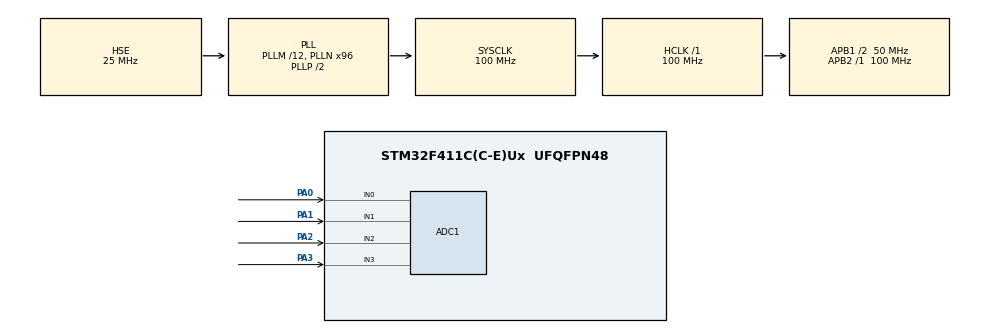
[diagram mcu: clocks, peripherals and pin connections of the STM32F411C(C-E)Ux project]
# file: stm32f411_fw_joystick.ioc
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Mcu.Family=STM32F4
RCC.PLLSourceVirtual=RCC_PLLSOURCE_HSE
PC15-OSC32_OUT.Mode=LSE-External-Oscillator
Dma.ADC1.0.Instance=DMA2_Stream0
RCC.CortexFreq_Value=100000000
ADC1.ContinuousConvMode=ENABLE
SH.ADCx_IN2.0=ADC1_IN2,IN2
ADC1.SamplingTime-6\#ChannelRegularConversion=ADC_SAMPLETIME_84CYCLES
ADC1.Rank-8\#ChannelRegularConversion=4
PH1\ -\ OSC_OUT.Mode=HSE-External-Oscillator
RCC.APB1CLKDivider=RCC_HCLK_DIV2
PC14-OSC32_IN.Signal=RCC_OSC32_IN
ADC1.SamplingTime-2\#ChannelRegularConversion=ADC_SAMPLETIME_84CYCLES
ADC1.Channel-8\#ChannelRegularConversion=ADC_CHANNEL_3
RCC.SYSCLKSource=RCC_SYSCLKSOURCE_PLLCLK
ProjectManager.StackSize=0x400
PA0-WKUP.Signal=ADCx_IN0
ADC1.Channel-7\#ChannelRegularConversion=ADC_CHANNEL_2
PA13.Signal=SYS_JTMS-SWDIO
Dma.ADC1.0.PeriphDataAlignment=DMA_PDATAALIGN_WORD
PH0\ -\ OSC_IN.Mode=HSE-External-Oscillator
PH0\ -\ OSC_IN.Signal=RCC_OSC_IN
ProjectManager.TargetToolchain=STM32CubeIDE
Dma.ADC1.0.Mode=DMA_CIRCULAR
RCC.HCLKFreq_Value=100000000
SH.ADCx_IN3.0=ADC1_IN3,IN3
Dma.ADC1.0.Priority=DMA_PRIORITY_MEDIUM
RCC.APB2TimFreq_Value=100000000
Dma.ADC1.0.Direction=DMA_PERIPH_TO_MEMORY
ADC1.Channel-2\#ChannelRegularConversion=ADC_CHANNEL_0
NVIC.DMA2_Stream0_IRQn=true\:0\:0\:false\:false\:true\:false\:true
PC15-OSC32_OUT.Signal=RCC_OSC32_OUT
Dma.ADC1.0.MemDataAlignment=DMA_MDATAALIGN_WORD
PA1.Signal=ADCx_IN1
RCC.AHBFreq_Value=100000000
RCC.HSE_VALUE=25000000
PH1\ -\ OSC_OUT.Signal=RCC_OSC_OUT
ADC1.ScanConvMode=ENABLE
board=custom
RCC.VCOOutputFreq_Value=200000000
ADC1.Channel-6\#ChannelRegularConversion=ADC_CHANNEL_1
RCC.APB2Freq_Value=100000000
ADC1.Rank-2\#ChannelRegularConversion=1
PC14-OSC32_IN.Mode=LSE-External-Oscillator
PA14.Mode=Serial_Wire
Dma.ADC1.0.PeriphInc=DMA_PINC_DISABLE
SH.ADCx_IN0.0=ADC1_IN0,IN0
ADC1.DMAContinuousRequests=ENABLE
ADC1.NbrOfConversion=4
PA13.Mode=Serial_Wire
Mcu.Name=STM32F411C(C-E)Ux
PA2.Signal=ADCx_IN2
RCC.48MHZClocksFreq_Value=50000000
RCC.SYSCLKFreq_VALUE=100000000
Mcu.Package=UFQFPN48
ADC1.master=1
PA14.Signal=SYS_JTCK-SWCLK
Dma.ADC1.0.MemInc=DMA_MINC_ENABLE
ProjectManager.HeapSize=0x200
RCC.HSI_VALUE=16000000
ADC1.Rank-7\#ChannelRegularConversion=3
NVIC.PriorityGroup=NVIC_PRIORITYGROUP_4
ADC1.NbrOfConversionFlag=1
SH.ADCx_IN1.0=ADC1_IN1,IN1
RCC.PLLM=12
RCC.PLLN=96
RCC.APB1TimFreq_Value=100000000
Dma.ADC1.0.FIFOMode=DMA_FIFOMODE_DISABLE
ADC1.SamplingTime-7\#ChannelRegularConversion=ADC_SAMPLETIME_84CYCLES
ADC1.Rank-6\#ChannelRegularConversion=2
Dma.Request0=ADC1
RCC.APB1Freq_Value=50000000
ADC1.SamplingTime-8\#ChannelRegularConversion=ADC_SAMPLETIME_84CYCLES
ADC1.ClockPrescaler=ADC_CLOCK_SYNC_PCLK_DIV4
PA3.Signal=ADCx_IN3

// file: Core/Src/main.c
/* USER CODE BEGIN Header */
/**
  ******************************************************************************
  * @file           : main.c
  * @brief          : Main program body
  ******************************************************************************
  * @attention
  *
  * <h2><center>&copy; Copyright (c) 2021 STMicroelectronics.
  * All rights reserved.</center></h2>
  *
  * This software component is licensed by ST under BSD 3-Clause license,
  * the "License"; You may not use this file except in compliance with the
  * License. You may obtain a copy of the License at:
  *                        opensource.org/licenses/BSD-3-Clause
  *
  ******************************************************************************
  */
/* USER CODE END Header */
#include "main.h"
#include "adc.h"
#include "dma.h"
#include "gpio.h"

/* USER CODE BEGIN Includes */

#include "joystick.h"

/* USER CODE END Includes */

void SystemClock_Config(void);

int main(void)
{

  /* MCU Configuration--------------------------------------------------------*/

  /* Reset of all peripherals, Initializes the Flash interface and the Systick. */
  HAL_Init();

  /* Configure the system clock */
  SystemClock_Config();

  /* Initialize all configured peripherals */
  MX_GPIO_Init();
  MX_DMA_Init();
  MX_ADC1_Init();
  /* USER CODE BEGIN 2 */

  joystick_init();

  /* USER CODE END 2 */

  /* Infinite loop */
  while (1)
  {

  }
}

void SystemClock_Config(void)
{
  RCC_OscInitTypeDef RCC_OscInitStruct = {0};
  RCC_ClkInitTypeDef RCC_ClkInitStruct = {0};

  /** Configure the main internal regulator output voltage
  */
  __HAL_RCC_PWR_CLK_ENABLE();
  __HAL_PWR_VOLTAGESCALING_CONFIG(PWR_REGULATOR_VOLTAGE_SCALE1);
  /** Initializes the RCC Oscillators according to the specified parameters
  * in the RCC_OscInitTypeDef structure.
  */
  RCC_OscInitStruct.OscillatorType = RCC_OSCILLATORTYPE_HSE;
  RCC_OscInitStruct.HSEState = RCC_HSE_ON;
  RCC_OscInitStruct.PLL.PLLState = RCC_PLL_ON;
  RCC_OscInitStruct.PLL.PLLSource = RCC_PLLSOURCE_HSE;
  RCC_OscInitStruct.PLL.PLLM = 12;
  RCC_OscInitStruct.PLL.PLLN = 96;
  RCC_OscInitStruct.PLL.PLLP = RCC_PLLP_DIV2;
  RCC_OscInitStruct.PLL.PLLQ = 4;
  if (HAL_RCC_OscConfig(&RCC_OscInitStruct) != HAL_OK)
  {
    Error_Handler();
  }
  /** Initializes the CPU, AHB and APB buses clocks
  */
  RCC_ClkInitStruct.ClockType = RCC_CLOCKTYPE_HCLK|RCC_CLOCKTYPE_SYSCLK
                              |RCC_CLOCKTYPE_PCLK1|RCC_CLOCKTYPE_PCLK2;
  RCC_ClkInitStruct.SYSCLKSource = RCC_SYSCLKSOURCE_PLLCLK;
  RCC_ClkInitStruct.AHBCLKDivider = RCC_SYSCLK_DIV1;
  RCC_ClkInitStruct.APB1CLKDivider = RCC_HCLK_DIV2;
  RCC_ClkInitStruct.APB2CLKDivider = RCC_HCLK_DIV1;

  if (HAL_RCC_ClockConfig(&RCC_ClkInitStruct, FLASH_LATENCY_3) != HAL_OK)
  {
    Error_Handler();
  }
}

void Error_Handler(void)
{
  __disable_irq();
  while (1)
  {
  }
}

/************************ (C) COPYRIGHT STMicroelectronics *****END OF FILE****/
